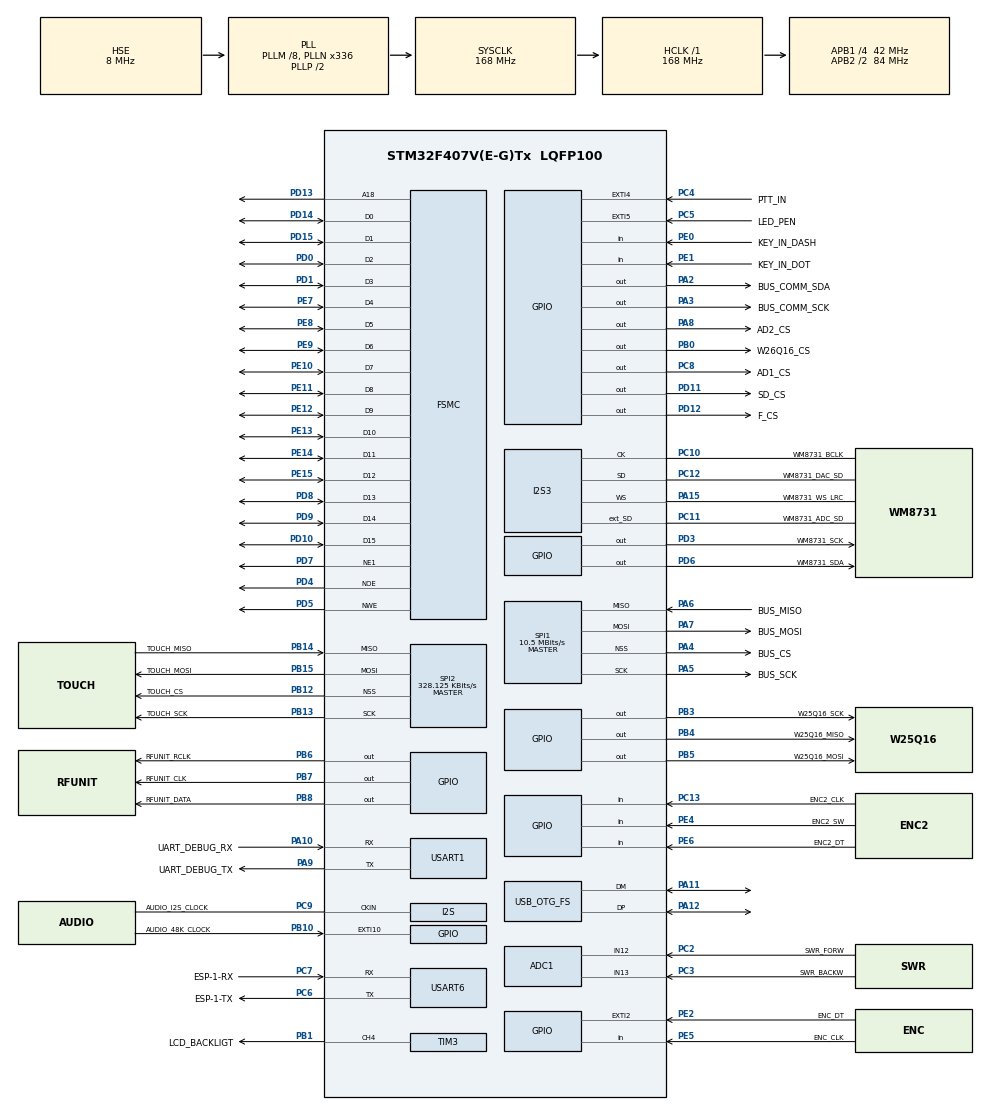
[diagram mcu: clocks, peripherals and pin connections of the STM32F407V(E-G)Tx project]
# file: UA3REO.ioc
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ADC1.Channel-0\#ChannelRegularConversion=ADC_CHANNEL_12
ADC1.NbrOfConversionFlag=1
ADC1.Rank-0\#ChannelRegularConversion=1
ADC1.SamplingTime-0\#ChannelRegularConversion=ADC_SAMPLETIME_3CYCLES
ADC1.master=1
Dma.I2S3_EXT_RX.0.Direction=DMA_PERIPH_TO_MEMORY
Dma.I2S3_EXT_RX.0.FIFOMode=DMA_FIFOMODE_ENABLE
Dma.I2S3_EXT_RX.0.FIFOThreshold=DMA_FIFO_THRESHOLD_FULL
Dma.I2S3_EXT_RX.0.Instance=DMA1_Stream0
Dma.I2S3_EXT_RX.0.MemBurst=DMA_MBURST_SINGLE
Dma.I2S3_EXT_RX.0.MemDataAlignment=DMA_MDATAALIGN_HALFWORD
Dma.I2S3_EXT_RX.0.MemInc=DMA_MINC_ENABLE
Dma.I2S3_EXT_RX.0.Mode=DMA_CIRCULAR
Dma.I2S3_EXT_RX.0.PeriphBurst=DMA_PBURST_SINGLE
Dma.I2S3_EXT_RX.0.PeriphDataAlignment=DMA_PDATAALIGN_HALFWORD
Dma.I2S3_EXT_RX.0.PeriphInc=DMA_PINC_DISABLE
Dma.I2S3_EXT_RX.0.Priority=DMA_PRIORITY_VERY_HIGH
Dma.MEMTOMEM.2.Direction=DMA_MEMORY_TO_MEMORY
Dma.MEMTOMEM.2.FIFOMode=DMA_FIFOMODE_ENABLE
Dma.MEMTOMEM.2.FIFOThreshold=DMA_FIFO_THRESHOLD_FULL
Dma.MEMTOMEM.2.Instance=DMA2_Stream0
Dma.MEMTOMEM.2.MemBurst=DMA_MBURST_INC4
Dma.MEMTOMEM.2.MemDataAlignment=DMA_MDATAALIGN_WORD
Dma.MEMTOMEM.2.MemInc=DMA_MINC_ENABLE
Dma.MEMTOMEM.2.Mode=DMA_NORMAL
Dma.MEMTOMEM.2.PeriphBurst=DMA_PBURST_INC4
Dma.MEMTOMEM.2.PeriphDataAlignment=DMA_PDATAALIGN_WORD
Dma.MEMTOMEM.2.PeriphInc=DMA_PINC_ENABLE
Dma.MEMTOMEM.2.Priority=DMA_PRIORITY_HIGH
Dma.MEMTOMEM.3.Direction=DMA_MEMORY_TO_MEMORY
Dma.MEMTOMEM.3.FIFOMode=DMA_FIFOMODE_ENABLE
Dma.MEMTOMEM.3.FIFOThreshold=DMA_FIFO_THRESHOLD_FULL
Dma.MEMTOMEM.3.Instance=DMA2_Stream1
Dma.MEMTOMEM.3.MemBurst=DMA_MBURST_INC4
Dma.MEMTOMEM.3.MemDataAlignment=DMA_MDATAALIGN_WORD
Dma.MEMTOMEM.3.MemInc=DMA_MINC_ENABLE
Dma.MEMTOMEM.3.Mode=DMA_NORMAL
Dma.MEMTOMEM.3.PeriphBurst=DMA_PBURST_INC4
Dma.MEMTOMEM.3.PeriphDataAlignment=DMA_PDATAALIGN_WORD
Dma.MEMTOMEM.3.PeriphInc=DMA_PINC_ENABLE
Dma.MEMTOMEM.3.Priority=DMA_PRIORITY_HIGH
Dma.MEMTOMEM.4.Direction=DMA_MEMORY_TO_MEMORY
Dma.MEMTOMEM.4.FIFOMode=DMA_FIFOMODE_ENABLE
Dma.MEMTOMEM.4.FIFOThreshold=DMA_FIFO_THRESHOLD_FULL
Dma.MEMTOMEM.4.Instance=DMA2_Stream7
Dma.MEMTOMEM.4.MemBurst=DMA_MBURST_INC4
Dma.MEMTOMEM.4.MemDataAlignment=DMA_MDATAALIGN_WORD
Dma.MEMTOMEM.4.MemInc=DMA_MINC_ENABLE
Dma.MEMTOMEM.4.Mode=DMA_NORMAL
Dma.MEMTOMEM.4.PeriphBurst=DMA_PBURST_INC4
Dma.MEMTOMEM.4.PeriphDataAlignment=DMA_PDATAALIGN_WORD
Dma.MEMTOMEM.4.PeriphInc=DMA_PINC_ENABLE
Dma.MEMTOMEM.4.Priority=DMA_PRIORITY_LOW
Dma.MEMTOMEM.5.Direction=DMA_MEMORY_TO_MEMORY
Dma.MEMTOMEM.5.FIFOMode=DMA_FIFOMODE_ENABLE
Dma.MEMTOMEM.5.FIFOThreshold=DMA_FIFO_THRESHOLD_FULL
Dma.MEMTOMEM.5.Instance=DMA2_Stream6
Dma.MEMTOMEM.5.MemBurst=DMA_MBURST_INC8
Dma.MEMTOMEM.5.MemDataAlignment=DMA_MDATAALIGN_HALFWORD
Dma.MEMTOMEM.5.MemInc=DMA_MINC_DISABLE
Dma.MEMTOMEM.5.Mode=DMA_NORMAL
Dma.MEMTOMEM.5.PeriphBurst=DMA_PBURST_INC8
Dma.MEMTOMEM.5.PeriphDataAlignment=DMA_PDATAALIGN_HALFWORD
Dma.MEMTOMEM.5.PeriphInc=DMA_PINC_ENABLE
Dma.MEMTOMEM.5.Priority=DMA_PRIORITY_LOW
Dma.MEMTOMEM.6.Direction=DMA_MEMORY_TO_MEMORY
Dma.MEMTOMEM.6.FIFOMode=DMA_FIFOMODE_ENABLE
Dma.MEMTOMEM.6.FIFOThreshold=DMA_FIFO_THRESHOLD_FULL
Dma.MEMTOMEM.6.Instance=DMA2_Stream5
Dma.MEMTOMEM.6.MemBurst=DMA_MBURST_INC8
Dma.MEMTOMEM.6.MemDataAlignment=DMA_MDATAALIGN_HALFWORD
Dma.MEMTOMEM.6.MemInc=DMA_MINC_DISABLE
Dma.MEMTOMEM.6.Mode=DMA_NORMAL
Dma.MEMTOMEM.6.PeriphBurst=DMA_PBURST_INC8
Dma.MEMTOMEM.6.PeriphDataAlignment=DMA_PDATAALIGN_HALFWORD
Dma.MEMTOMEM.6.PeriphInc=DMA_PINC_DISABLE
Dma.MEMTOMEM.6.Priority=DMA_PRIORITY_MEDIUM
Dma.MEMTOMEM.7.Direction=DMA_MEMORY_TO_MEMORY
Dma.MEMTOMEM.7.FIFOMode=DMA_FIFOMODE_ENABLE
Dma.MEMTOMEM.7.FIFOThreshold=DMA_FIFO_THRESHOLD_FULL
Dma.MEMTOMEM.7.Instance=DMA2_Stream3
Dma.MEMTOMEM.7.MemBurst=DMA_MBURST_INC4
Dma.MEMTOMEM.7.MemDataAlignment=DMA_MDATAALIGN_WORD
Dma.MEMTOMEM.7.MemInc=DMA_MINC_ENABLE
Dma.MEMTOMEM.7.Mode=DMA_NORMAL
Dma.MEMTOMEM.7.PeriphBurst=DMA_PBURST_INC4
Dma.MEMTOMEM.7.PeriphDataAlignment=DMA_PDATAALIGN_WORD
Dma.MEMTOMEM.7.PeriphInc=DMA_PINC_ENABLE
Dma.MEMTOMEM.7.Priority=DMA_PRIORITY_HIGH
Dma.Request0=I2S3_EXT_RX
Dma.Request1=SPI3_TX
Dma.Request2=MEMTOMEM
Dma.Request3=MEMTOMEM
Dma.Request4=MEMTOMEM
Dma.Request5=MEMTOMEM
Dma.Request6=MEMTOMEM
Dma.Request7=MEMTOMEM
Dma.Request8=USART6_RX
Dma.SPI3_TX.1.Direction=DMA_MEMORY_TO_PERIPH
Dma.SPI3_TX.1.FIFOMode=DMA_FIFOMODE_ENABLE
Dma.SPI3_TX.1.FIFOThreshold=DMA_FIFO_THRESHOLD_FULL
Dma.SPI3_TX.1.Instance=DMA1_Stream5
Dma.SPI3_TX.1.MemBurst=DMA_MBURST_SINGLE
Dma.SPI3_TX.1.MemDataAlignment=DMA_MDATAALIGN_HALFWORD
Dma.SPI3_TX.1.MemInc=DMA_MINC_ENABLE
Dma.SPI3_TX.1.Mode=DMA_CIRCULAR
Dma.SPI3_TX.1.PeriphBurst=DMA_PBURST_SINGLE
Dma.SPI3_TX.1.PeriphDataAlignment=DMA_PDATAALIGN_HALFWORD
Dma.SPI3_TX.1.PeriphInc=DMA_PINC_DISABLE
Dma.SPI3_TX.1.Priority=DMA_PRIORITY_VERY_HIGH
Dma.USART6_RX.8.Direction=DMA_PERIPH_TO_MEMORY
Dma.USART6_RX.8.FIFOMode=DMA_FIFOMODE_DISABLE
Dma.USART6_RX.8.Instance=DMA2_Stream2
Dma.USART6_RX.8.MemDataAlignment=DMA_MDATAALIGN_BYTE
Dma.USART6_RX.8.MemInc=DMA_MINC_ENABLE
Dma.USART6_RX.8.Mode=DMA_CIRCULAR
Dma.USART6_RX.8.PeriphDataAlignment=DMA_PDATAALIGN_BYTE
Dma.USART6_RX.8.PeriphInc=DMA_PINC_DISABLE
Dma.USART6_RX.8.Priority=DMA_PRIORITY_MEDIUM
FSMC.AddressSetupTime1=2
FSMC.BusTurnAroundDuration1=5
FSMC.DataSetupTime1=5
FSMC.ExtendedAddressSetupTime1=2
FSMC.ExtendedBusTurnAroundDuration1=3
FSMC.ExtendedDataSetupTime1=5
FSMC.ExtendedMode1=FSMC_EXTENDED_MODE_ENABLE
I2S3.AudioFreq=I2S_AUDIOFREQ_48K
I2S3.CPOL=I2S_CPOL_LOW
I2S3.ClockSource=I2S_CLOCK_EXTERNAL
I2S3.DataFormat=I2S_DATAFORMAT_32B
I2S3.ErrorAudioFreq=0.0 %
I2S3.FullDuplexMode=I2S_FULLDUPLEXMODE_ENABLE
I2S3.Instance=SPI$Index
I2S3.Mode=I2S_MODE_MASTER_TX
I2S3.RealAudioFreq=48.0 KHz
I2S3.Standard=I2S_STANDARD_PHILIPS
I2S3.VirtualMode=I2S_MODE_MASTER
IWDG.Prescaler=IWDG_PRESCALER_32
Mcu.Family=STM32F4
Mcu.Name=STM32F407V(E-G)Tx
Mcu.Package=LQFP100
NVIC.DMA1_Stream0_IRQn=true\:0\:0\:false\:false\:true\:false\:true
NVIC.DMA1_Stream5_IRQn=true\:0\:0\:false\:false\:true\:false\:true
NVIC.DMA2_Stream0_IRQn=true\:4\:0\:true\:false\:true\:true\:true
NVIC.DMA2_Stream1_IRQn=true\:4\:0\:true\:false\:true\:true\:true
NVIC.DMA2_Stream2_IRQn=true\:0\:0\:false\:false\:true\:false\:true
NVIC.DMA2_Stream3_IRQn=true\:0\:0\:false\:false\:true\:true\:true
NVIC.DMA2_Stream6_IRQn=true\:5\:0\:true\:false\:true\:true\:true
NVIC.EXTI15_10_IRQn=true\:2\:0\:true\:false\:true\:true\:true
NVIC.EXTI2_IRQn=true\:3\:0\:true\:false\:true\:true\:true
NVIC.EXTI4_IRQn=true\:6\:0\:true\:false\:true\:true\:true
NVIC.EXTI9_5_IRQn=true\:5\:0\:true\:false\:true\:true\:true
NVIC.OTG_FS_IRQn=true\:1\:0\:true\:false\:true\:true\:true
NVIC.PriorityGroup=NVIC_PRIORITYGROUP_4
NVIC.SPI1_IRQn=true\:0\:0\:true\:false\:true\:true\:true
NVIC.TIM4_IRQn=true\:8\:0\:true\:false\:true\:true\:true
NVIC.TIM5_IRQn=true\:4\:0\:true\:false\:true\:true\:true
NVIC.TIM6_DAC_IRQn=true\:7\:0\:true\:false\:true\:true\:true
NVIC.TIM7_IRQn=true\:9\:0\:true\:false\:true\:true\:true
NVIC.USART6_IRQn=true\:0\:0\:false\:false\:true\:true\:true
PA10.GPIO_Label=UART_DEBUG_RX
PA10.GPIO_Speed=GPIO_SPEED_FREQ_MEDIUM
PA10.Mode=Asynchronous
PA10.Signal=USART1_RX
PA11.Mode=Device_Only
PA11.Signal=USB_OTG_FS_DM
PA12.Mode=Device_Only
PA12.Signal=USB_OTG_FS_DP
PA13.Mode=Serial_Wire
PA13.Signal=SYS_JTMS-SWDIO
PA14.Mode=Serial_Wire
PA14.Signal=SYS_JTCK-SWCLK
PA15.GPIO_Label=WM8731_WS_LRC
PA15.GPIO_PuPd=GPIO_PULLUP
PA15.GPIO_Speed=GPIO_SPEED_FREQ_VERY_HIGH
PA15.Mode=Full_Duplex_Master
PA15.Signal=I2S3_WS
PA2.GPIO_Label=BUS_COMM_SDA
PA2.GPIO_PuPd=GPIO_PULLUP
PA2.Signal=GPIO_Output
PA3.GPIO_Label=BUS_COMM_SCK
PA3.GPIO_PuPd=GPIO_PULLUP
PA3.Signal=GPIO_Output
PA4.GPIO_Label=BUS_CS
PA4.GPIO_PuPd=GPIO_PULLUP
PA4.Mode=NSS_Signal_Hard_Output
PA4.Signal=SPI1_NSS
PA5.GPIO_Label=BUS_SCK
PA5.GPIO_PuPd=GPIO_PULLUP
PA5.GPIO_Speed=GPIO_SPEED_FREQ_VERY_HIGH
PA5.Mode=Full_Duplex_Master
PA5.Signal=SPI1_SCK
PA6.GPIO_Label=BUS_MISO
PA6.GPIO_PuPd=GPIO_PULLUP
PA6.GPIO_Speed=GPIO_SPEED_FREQ_VERY_HIGH
PA6.Mode=Full_Duplex_Master
PA6.Signal=SPI1_MISO
PA7.GPIO_Label=BUS_MOSI
PA7.GPIO_PuPd=GPIO_PULLUP
PA7.GPIO_Speed=GPIO_SPEED_FREQ_VERY_HIGH
PA7.Mode=Full_Duplex_Master
PA7.Signal=SPI1_MOSI
PA8.GPIO_Label=AD2_CS
PA8.Signal=GPIO_Output
PA9.GPIO_Label=UART_DEBUG_TX
PA9.GPIO_Speed=GPIO_SPEED_FREQ_MEDIUM
PA9.Mode=Asynchronous
PA9.Signal=USART1_TX
PB0.GPIO_Label=W26Q16_CS
PB0.GPIO_PuPd=GPIO_PULLUP
PB0.GPIO_Speed=GPIO_SPEED_FREQ_VERY_HIGH
PB0.Signal=GPIO_Output
PB1.GPIO_Label=LCD_BACKLIGT
PB1.GPIO_Speed=GPIO_SPEED_FREQ_LOW
PB1.Signal=S_TIM3_CH4
PB10.GPIO_Label=AUDIO_48K_CLOCK
PB10.GPIO_PuPd=GPIO_PULLUP
PB10.Signal=GPXTI10
PB12.GPIO_Label=TOUCH_CS
PB12.GPIO_PuPd=GPIO_PULLUP
PB12.GPIO_Speed=GPIO_SPEED_FREQ_HIGH
PB12.Mode=NSS_Signal_Hard_Output
PB12.Signal=SPI2_NSS
PB13.GPIO_Label=TOUCH_SCK
PB13.GPIO_PuPd=GPIO_PULLUP
PB13.GPIO_Speed=GPIO_SPEED_FREQ_HIGH
PB13.Mode=Full_Duplex_Master
PB13.Signal=SPI2_SCK
PB14.GPIO_Label=TOUCH_MISO
PB14.GPIO_PuPd=GPIO_PULLUP
PB14.GPIO_Speed=GPIO_SPEED_FREQ_HIGH
PB14.Mode=Full_Duplex_Master
PB14.Signal=SPI2_MISO
PB15.GPIO_Label=TOUCH_MOSI
PB15.GPIO_PuPd=GPIO_PULLUP
PB15.GPIO_Speed=GPIO_SPEED_FREQ_HIGH
PB15.Mode=Full_Duplex_Master
PB15.Signal=SPI2_MOSI
PB3.GPIO_Label=W25Q16_SCK
PB3.Signal=GPIO_Output
PB4.GPIO_Label=W25Q16_MISO
PB4.Signal=GPIO_Output
PB5.GPIO_Label=W25Q16_MOSI
PB5.Signal=GPIO_Output
PB6.GPIO_Label=RFUNIT_RCLK
PB6.GPIO_PuPd=GPIO_PULLUP
PB6.Signal=GPIO_Output
PB7.GPIO_Label=RFUNIT_CLK
PB7.GPIO_PuPd=GPIO_PULLUP
PB7.Signal=GPIO_Output
PB8.GPIO_Label=RFUNIT_DATA
PB8.GPIO_PuPd=GPIO_PULLUP
PB8.Signal=GPIO_Output
PC10.GPIO_Label=WM8731_BCLK
PC10.GPIO_PuPd=GPIO_PULLUP
PC10.GPIO_Speed=GPIO_SPEED_FREQ_VERY_HIGH
PC10.Mode=Full_Duplex_Master
PC10.Signal=I2S3_CK
PC11.GPIO_Label=WM8731_ADC_SD
PC11.GPIO_PuPd=GPIO_PULLUP
PC11.GPIO_Speed=GPIO_SPEED_FREQ_VERY_HIGH
PC11.Mode=Full_Duplex_Master
PC11.Signal=I2S3_ext_SD
PC12.GPIO_Label=WM8731_DAC_SD
PC12.GPIO_PuPd=GPIO_PULLUP
PC12.GPIO_Speed=GPIO_SPEED_FREQ_VERY_HIGH
PC12.Mode=Full_Duplex_Master
PC12.Signal=I2S3_SD
PC13-ANTI_TAMP.GPIO_Label=ENC2_CLK
PC13-ANTI_TAMP.Signal=GPIO_Input
PC14-OSC32_IN.Mode=LSE-External-Oscillator
PC14-OSC32_IN.Signal=RCC_OSC32_IN
PC15-OSC32_OUT.Mode=LSE-External-Oscillator
PC15-OSC32_OUT.Signal=RCC_OSC32_OUT
PC2.GPIO_Label=SWR_FORW
PC2.Signal=ADCx_IN12
PC3.GPIO_Label=SWR_BACKW
PC3.Signal=ADCx_IN13
PC4.GPIO_Label=PTT_IN
PC4.GPIO_PuPd=GPIO_PULLUP
PC4.Signal=GPXTI4
PC5.GPIO_Label=LED_PEN
PC5.GPIO_ModeDefaultEXTI=GPIO_MODE_IT_RISING_FALLING
PC5.GPIO_PuPd=GPIO_PULLUP
PC5.Signal=GPXTI5
PC6.GPIO_Label=ESP-1-TX
PC6.Mode=Asynchronous
PC6.Signal=USART6_TX
PC7.GPIO_Label=ESP-1-RX
PC7.Mode=Asynchronous
PC7.Signal=USART6_RX
PC8.GPIO_Label=AD1_CS
PC8.Signal=GPIO_Output
PC9.GPIO_Label=AUDIO_I2S_CLOCK
PC9.GPIO_PuPd=GPIO_PULLUP
PC9.GPIO_Speed=GPIO_SPEED_FREQ_VERY_HIGH
PC9.Mode=Audio_ClockIn
PC9.Signal=I2S_CKIN
PD0.GPIO_PuPd=GPIO_PULLUP
PD0.GPIO_Speed_High_Default=GPIO_SPEED_FREQ_LOW
PD0.Mode=16b-d1
PD0.Signal=FSMC_D2
PD1.GPIO_PuPd=GPIO_PULLUP
PD1.GPIO_Speed_High_Default=GPIO_SPEED_FREQ_LOW
PD1.Mode=16b-d1
PD1.Signal=FSMC_D3
PD10.GPIO_PuPd=GPIO_PULLUP
PD10.GPIO_Speed_High_Default=GPIO_SPEED_FREQ_LOW
PD10.Mode=16b-d1
PD10.Signal=FSMC_D15
PD11.GPIO_Label=SD_CS
PD11.Signal=GPIO_Output
PD12.GPIO_Label=F_CS
PD12.Signal=GPIO_Output
PD13.GPIO_PuPd=GPIO_PULLUP
PD13.GPIO_Speed_High_Default=GPIO_SPEED_FREQ_LOW
PD13.Mode=A18_1
PD13.Signal=FSMC_A18
PD14.GPIO_PuPd=GPIO_PULLUP
PD14.GPIO_Speed_High_Default=GPIO_SPEED_FREQ_LOW
PD14.Mode=16b-d1
PD14.Signal=FSMC_D0
PD15.GPIO_PuPd=GPIO_PULLUP
PD15.GPIO_Speed_High_Default=GPIO_SPEED_FREQ_LOW
PD15.Mode=16b-d1
PD15.Signal=FSMC_D1
PD3.GPIO_Label=WM8731_SCK
PD3.GPIO_PuPd=GPIO_PULLUP
PD3.GPIO_Speed=GPIO_SPEED_FREQ_LOW
PD3.Signal=GPIO_Output
PD4.GPIO_PuPd=GPIO_PULLUP
PD4.GPIO_Speed_High_Default=GPIO_SPEED_FREQ_LOW
PD4.Mode=Lcd1
PD4.Signal=FSMC_NOE
PD5.GPIO_PuPd=GPIO_PULLUP
PD5.GPIO_Speed_High_Default=GPIO_SPEED_FREQ_LOW
PD5.Mode=Lcd1
PD5.Signal=FSMC_NWE
PD6.GPIO_Label=WM8731_SDA
PD6.GPIO_PuPd=GPIO_PULLUP
PD6.GPIO_Speed=GPIO_SPEED_FREQ_LOW
PD6.Signal=GPIO_Output
PD7.GPIO_PuPd=GPIO_PULLUP
PD7.GPIO_Speed_High_Default=GPIO_SPEED_FREQ_LOW
PD7.Mode=NorPsramChipSelect1_1
PD7.Signal=FSMC_NE1
PD8.GPIO_PuPd=GPIO_PULLUP
PD8.GPIO_Speed_High_Default=GPIO_SPEED_FREQ_LOW
PD8.Mode=16b-d1
PD8.Signal=FSMC_D13
PD9.GPIO_PuPd=GPIO_PULLUP
PD9.GPIO_Speed_High_Default=GPIO_SPEED_FREQ_LOW
PD9.Mode=16b-d1
PD9.Signal=FSMC_D14
PE0.GPIO_Label=KEY_IN_DASH
PE0.GPIO_PuPd=GPIO_PULLUP
PE0.Signal=GPIO_Input
PE1.GPIO_Label=KEY_IN_DOT
PE1.GPIO_PuPd=GPIO_PULLUP
PE1.Signal=GPIO_Input
PE10.GPIO_PuPd=GPIO_PULLUP
PE10.GPIO_Speed_High_Default=GPIO_SPEED_FREQ_LOW
PE10.Mode=16b-d1
PE10.Signal=FSMC_D7
PE11.GPIO_PuPd=GPIO_PULLUP
PE11.GPIO_Speed_High_Default=GPIO_SPEED_FREQ_LOW
PE11.Mode=16b-d1
PE11.Signal=FSMC_D8
PE12.GPIO_PuPd=GPIO_PULLUP
PE12.GPIO_Speed_High_Default=GPIO_SPEED_FREQ_LOW
PE12.Mode=16b-d1
PE12.Signal=FSMC_D9
PE13.GPIO_PuPd=GPIO_PULLUP
PE13.GPIO_Speed_High_Default=GPIO_SPEED_FREQ_LOW
PE13.Mode=16b-d1
PE13.Signal=FSMC_D10
PE14.GPIO_PuPd=GPIO_PULLUP
PE14.GPIO_Speed_High_Default=GPIO_SPEED_FREQ_LOW
PE14.Mode=16b-d1
PE14.Signal=FSMC_D11
PE15.GPIO_PuPd=GPIO_PULLUP
PE15.GPIO_Speed_High_Default=GPIO_SPEED_FREQ_LOW
PE15.Mode=16b-d1
PE15.Signal=FSMC_D12
PE2.GPIO_Label=ENC_DT
PE2.GPIO_ModeDefaultEXTI=GPIO_MODE_IT_RISING_FALLING
PE2.GPIO_PuPd=GPIO_PULLUP
PE2.Signal=GPXTI2
PE4.GPIO_Label=ENC2_SW
PE4.Signal=GPIO_Input
PE5.GPIO_Label=ENC_CLK
PE5.GPIO_PuPd=GPIO_PULLUP
PE5.Signal=GPIO_Input
PE6.GPIO_Label=ENC2_DT
PE6.Signal=GPIO_Input
PE7.GPIO_PuPd=GPIO_PULLUP
PE7.GPIO_Speed_High_Default=GPIO_SPEED_FREQ_LOW
PE7.Mode=16b-d1
PE7.Signal=FSMC_D4
PE8.GPIO_PuPd=GPIO_PULLUP
PE8.GPIO_Speed_High_Default=GPIO_SPEED_FREQ_LOW
PE8.Mode=16b-d1
PE8.Signal=FSMC_D5
PE9.GPIO_PuPd=GPIO_PULLUP
PE9.GPIO_Speed_High_Default=GPIO_SPEED_FREQ_LOW
PE9.Mode=16b-d1
PE9.Signal=FSMC_D6
PH0-OSC_IN.Mode=HSE-External-Oscillator
PH0-OSC_IN.Signal=RCC_OSC_IN
PH1-OSC_OUT.Mode=HSE-External-Oscillator
PH1-OSC_OUT.Signal=RCC_OSC_OUT
ProjectManager.HeapSize=0x600
ProjectManager.StackSize=0xA00
ProjectManager.TargetToolchain=MDK-ARM V5
RCC.48MHZClocksFreq_Value=48000000
RCC.AHBFreq_Value=168000000
RCC.APB1CLKDivider=RCC_HCLK_DIV4
RCC.APB1Freq_Value=42000000
RCC.APB1TimFreq_Value=84000000
RCC.APB2CLKDivider=RCC_HCLK_DIV2
RCC.APB2Freq_Value=84000000
RCC.APB2TimFreq_Value=168000000
RCC.CortexFreq_Value=168000000
RCC.EXTERNAL_CLOCK_VALUE=12288000
RCC.EnbaleCSS=true
RCC.HCLKFreq_Value=168000000
RCC.HSE_VALUE=8000000
RCC.HSI_VALUE=16000000
RCC.I2SClockSource=I2S_CLOCK_EXTERNAL
RCC.PLLI2SN=384
RCC.PLLM=8
RCC.PLLN=336
RCC.PLLQ=7
RCC.RCC_RTC_Clock_Source=RCC_RTCCLKSOURCE_LSE
RCC.RCC_RTC_Clock_SourceVirtual=RCC_RTCCLKSOURCE_HSE_DIV8
RCC.RCC_RTC_Clock_Source_FROM_HSE=RCC_RTCCLKSOURCE_HSE_DIV8
RCC.SYSCLKFreq_VALUE=168000000
RCC.SYSCLKSource=RCC_SYSCLKSOURCE_PLLCLK
RCC.VCOOutputFreq_Value=336000000
RTC.SynchPrediv=255
SH.ADCx_IN12.0=ADC1_IN12,IN12
SH.ADCx_IN13.0=ADC1_IN13,IN13
SH.S_TIM3_CH4.0=TIM3_CH4,PWM Generation4 CH4
SPI1.BaudRatePrescaler=SPI_BAUDRATEPRESCALER_8
SPI1.CLKPhase=SPI_PHASE_1EDGE
SPI1.CLKPolarity=SPI_POLARITY_LOW
SPI1.CalculateBaudRate=10.5 MBits/s
SPI1.Direction=SPI_DIRECTION_2LINES
SPI1.Mode=SPI_MODE_MASTER
SPI1.VirtualNSS=VM_NSSHARD
SPI1.VirtualType=VM_MASTER
SPI2.BaudRatePrescaler=SPI_BAUDRATEPRESCALER_128
SPI2.CalculateBaudRate=328.125 KBits/s
SPI2.Direction=SPI_DIRECTION_2LINES
SPI2.Mode=SPI_MODE_MASTER
SPI2.VirtualNSS=VM_NSSHARD
SPI2.VirtualType=VM_MASTER
TIM3.Channel-PWM\ Generation4\ CH4=TIM_CHANNEL_4
TIM3.Period=65535
TIM3.Prescaler=0
TIM4.Period=1
TIM4.Prescaler=800
TIM4.TIM_MasterOutputTrigger=TIM_TRGO_UPDATE
TIM5.Period=1
TIM5.Prescaler=873
TIM5.TIM_MasterOutputTrigger=TIM_TRGO_UPDATE
TIM6.Period=99
TIM6.Prescaler=41999
TIM6.TIM_MasterOutputTrigger=TIM_TRGO_UPDATE
TIM7.Period=1
TIM7.Prescaler=800
TIM7.TIM_MasterOutputTrigger=TIM_TRGO_UPDATE
USART1.VirtualMode=VM_ASYNC
USART6.VirtualMode=VM_ASYNC
USB_OTG_FS.Sof_enable=ENABLE
USB_OTG_FS.VirtualMode=Device_Only
VP_IWDG_VS_IWDG.Mode=IWDG_Activate
VP_RTC_VS_RTC_Activate.Mode=RTC_Enabled
VP_TIM3_VS_ClockSourceINT.Mode=Internal
VP_TIM4_VS_ClockSourceINT.Mode=Internal
VP_TIM5_VS_ClockSourceINT.Mode=Internal
VP_TIM6_VS_ClockSourceINT.Mode=Enable_Timer
VP_TIM7_VS_ClockSourceINT.Mode=Enable_Timer
board=custom

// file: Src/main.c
/* USER CODE BEGIN Header */
/**
  ******************************************************************************
  * @file           : main.c
  * @brief          : Main program body
  ******************************************************************************
  * @attention
  *
  * <h2><center>&copy; Copyright (c) 2019 STMicroelectronics.
  * All rights reserved.</center></h2>
  *
  * This software component is licensed by ST under Ultimate Liberty license
  * SLA0044, the "License"; You may not use this file except in compliance with
  * the License. You may obtain a copy of the License at:
  *                             www.st.com/SLA0044
  *
  ******************************************************************************
  */
/* USER CODE END Header */

#include "main.h"

/* USER CODE BEGIN Includes */
#include "LCD/lcd_driver.h"
#include "LCD/xpt2046_spi.h"
#include "functions.h"
#include "bootloader.h"
#include "trx_manager.h"
#include "lcd.h"
#include "encoder.h"
#include "fpga.h"
#include "fft.h"
#include "wm8731.h"
#include "audio_processor.h"
#include "settings.h"
#include "profiler.h"
#include "usb_device.h"
#include "usbd_cat_if.h"
#include "wifi.h"
/* USER CODE END Includes */

ADC_HandleTypeDef hadc1;

I2S_HandleTypeDef hi2s3;
DMA_HandleTypeDef hdma_i2s3_ext_rx;
DMA_HandleTypeDef hdma_spi3_tx;

IWDG_HandleTypeDef hiwdg;

RTC_HandleTypeDef hrtc;

SPI_HandleTypeDef hspi1;
SPI_HandleTypeDef hspi2;

TIM_HandleTypeDef htim3;
TIM_HandleTypeDef htim4;
TIM_HandleTypeDef htim5;
TIM_HandleTypeDef htim6;
TIM_HandleTypeDef htim7;

UART_HandleTypeDef huart1;
UART_HandleTypeDef huart6;
DMA_HandleTypeDef hdma_usart6_rx;

PCD_HandleTypeDef hpcd_USB_OTG_FS;

DMA_HandleTypeDef hdma_memtomem_dma2_stream0;
DMA_HandleTypeDef hdma_memtomem_dma2_stream1;
DMA_HandleTypeDef hdma_memtomem_dma2_stream7;
DMA_HandleTypeDef hdma_memtomem_dma2_stream6;
DMA_HandleTypeDef hdma_memtomem_dma2_stream5;
DMA_HandleTypeDef hdma_memtomem_dma2_stream3;
SRAM_HandleTypeDef hsram1;

/* USER CODE BEGIN PV */
/* Private variables ---------------------------------------------------------*/
volatile uint32_t cpu_sleep_counter=0;
/* USER CODE END PV */

void SystemClock_Config(void);
static void MX_GPIO_Init(void);
static void MX_DMA_Init(void);
static void MX_FSMC_Init(void);
static void MX_TIM6_Init(void);
static void MX_I2S3_Init(void);
static void MX_TIM5_Init(void);
static void MX_SPI2_Init(void);
static void MX_SPI1_Init(void);
static void MX_TIM4_Init(void);
static void MX_RTC_Init(void);
static void MX_USART1_UART_Init(void);
static void MX_TIM3_Init(void);
static void MX_IWDG_Init(void);
static void MX_USB_OTG_FS_PCD_Init(void);
static void MX_ADC1_Init(void);
static void MX_TIM7_Init(void);
static void MX_USART6_UART_Init(void);
/* USER CODE BEGIN PFP */
/* Private function prototypes -----------------------------------------------*/

/* USER CODE END PFP */

int main(void)
{

  /* MCU Configuration--------------------------------------------------------*/

  /* Reset of all peripherals, Initializes the Flash interface and the Systick. */
  HAL_Init();

  /* USER CODE BEGIN Init */
	//checkBootloaderButton(); //Go to bootloader if (K0 PE4) pressed
  /* USER CODE END Init */

  /* Configure the system clock */
  SystemClock_Config();

  /* USER CODE BEGIN SysInit */
	MX_GPIO_Init();
	TRX_RF_UNIT_UpdateState(true);
  /* USER CODE END SysInit */

  /* Initialize all configured peripherals */
  MX_GPIO_Init();
  MX_DMA_Init();
  MX_FSMC_Init();
  MX_TIM6_Init();
  MX_I2S3_Init();
  MX_TIM5_Init();
  MX_SPI2_Init();
  MX_SPI1_Init();
  MX_TIM4_Init();
  MX_RTC_Init();
  MX_USART1_UART_Init();
  MX_TIM3_Init();
  MX_IWDG_Init();
  MX_ADC1_Init();
  MX_TIM7_Init();
  MX_USART6_UART_Init();
  /* USER CODE BEGIN 2 */
	MX_USB_DEVICE_Init();
	/* BUG FIX: Enabling Audio Clock Input in CubeMX does not set I2SSRC bit in RCC_CFGR register! Hence we need to set it manually here!
	  WARNING: A bug fix is also needed in __HAL_RCC_GET_I2S_SOURCE()
		Line 6131 stm32f4xx_hal_rcc_ex.h -> #define __HAL_RCC_GET_I2S_SOURCE() ((uint32_t)(READ_BIT(RCC->CFGR, RCC_CFGR_I2SSRC)) >> RCC_CFGR_I2SSRC_Pos)
	*/

	/*
	while(true)
	{
		i2c_begin(I2C_FPGA);
		i2c_beginTransmission_u8(I2C_FPGA, B8(1110010)); //I2C_ADDRESS
		i2c_write_u8(I2C_FPGA, 100);
		uint8_t st = i2c_endTransmission(I2C_FPGA);
		//sendToDebug_uint8(st,false);
		//sendToDebug_flush();

		i2c_begin(I2C_FPGA);
		i2c_requestFrom_ii(I2C_FPGA, B8(1110010), 3);
		sendToDebug_uint8(i2c_read(I2C_FPGA),false);
		sendToDebug_uint8(i2c_read(I2C_FPGA),false);
		sendToDebug_uint8(i2c_read(I2C_FPGA),false);
		sendToDebug_flush();

		sendToDebug_newline();

		HAL_IWDG_Refresh(&hiwdg);

		HAL_Delay(1000);
	}
	*/

	SPI_Bus_Buffer_TX[0]=1; //Q-M
	SPI_Bus_Buffer_TX[1]=2; //Q-L
	SPI_Bus_Buffer_TX[2]=4; //I-M
	SPI_Bus_Buffer_TX[3]=8; //I-L
	HAL_RTC_Init(&hrtc);
	InitProfiler();
	sendToDebug_str("\r\n");
	HAL_TIM_PWM_Start(&htim3, TIM_CHANNEL_4); //LCD backlight
	LoadSettings();
	LCD_Init();
	if(!TRX.Calibrated)
	{
		//Touch_Calibrate();
		LCD_Init();
		SaveSettings();
	}
	FFT_Init();
	WM8731_Init();
	TRX_Init();
	ENCODER_Init();
	FPGA_Init();
	initAudioProcessor();
	HAL_TIM_Base_Start(&htim5);
	HAL_TIM_Base_Start_IT(&htim5);
	HAL_TIM_Base_Start(&htim6);
	HAL_TIM_Base_Start_IT(&htim6);
	HAL_TIM_Base_Start(&htim4);
	HAL_TIM_Base_Start_IT(&htim4);
	HAL_TIM_Base_Start(&htim7);
	HAL_TIM_Base_Start_IT(&htim7);
	TRX_RF_UNIT_UpdateState(false);

	sendToDebug_str("UA3REO Started\r\n\r\n");
	TRX_inited = true;
  /* USER CODE END 2 */

  /* Infinite loop */
	while (1)
	{

    /* USER CODE BEGIN 3 */
		HAL_IWDG_Refresh(&hiwdg);
		cpu_sleep_counter++;
		__WFI();
	}
  /* USER CODE END 3 */
}

void SystemClock_Config(void)
{
  RCC_OscInitTypeDef RCC_OscInitStruct = {0};
  RCC_ClkInitTypeDef RCC_ClkInitStruct = {0};
  RCC_PeriphCLKInitTypeDef PeriphClkInitStruct = {0};

  /** Configure the main internal regulator output voltage
  */
  __HAL_RCC_PWR_CLK_ENABLE();
  __HAL_PWR_VOLTAGESCALING_CONFIG(PWR_REGULATOR_VOLTAGE_SCALE1);
  /** Initializes the CPU, AHB and APB busses clocks
  */
  RCC_OscInitStruct.OscillatorType = RCC_OSCILLATORTYPE_LSI|RCC_OSCILLATORTYPE_HSE
                              |RCC_OSCILLATORTYPE_LSE;
  RCC_OscInitStruct.HSEState = RCC_HSE_ON;
  RCC_OscInitStruct.LSEState = RCC_LSE_ON;
  RCC_OscInitStruct.LSIState = RCC_LSI_ON;
  RCC_OscInitStruct.PLL.PLLState = RCC_PLL_ON;
  RCC_OscInitStruct.PLL.PLLSource = RCC_PLLSOURCE_HSE;
  RCC_OscInitStruct.PLL.PLLM = 8;
  RCC_OscInitStruct.PLL.PLLN = 336;
  RCC_OscInitStruct.PLL.PLLP = RCC_PLLP_DIV2;
  RCC_OscInitStruct.PLL.PLLQ = 7;
  if (HAL_RCC_OscConfig(&RCC_OscInitStruct) != HAL_OK)
  {
    Error_Handler();
  }
  /** Initializes the CPU, AHB and APB busses clocks
  */
  RCC_ClkInitStruct.ClockType = RCC_CLOCKTYPE_HCLK|RCC_CLOCKTYPE_SYSCLK
                              |RCC_CLOCKTYPE_PCLK1|RCC_CLOCKTYPE_PCLK2;
  RCC_ClkInitStruct.SYSCLKSource = RCC_SYSCLKSOURCE_PLLCLK;
  RCC_ClkInitStruct.AHBCLKDivider = RCC_SYSCLK_DIV1;
  RCC_ClkInitStruct.APB1CLKDivider = RCC_HCLK_DIV4;
  RCC_ClkInitStruct.APB2CLKDivider = RCC_HCLK_DIV2;

  if (HAL_RCC_ClockConfig(&RCC_ClkInitStruct, FLASH_LATENCY_5) != HAL_OK)
  {
    Error_Handler();
  }
  PeriphClkInitStruct.PeriphClockSelection = RCC_PERIPHCLK_RTC;
  PeriphClkInitStruct.RTCClockSelection = RCC_RTCCLKSOURCE_LSE;
  if (HAL_RCCEx_PeriphCLKConfig(&PeriphClkInitStruct) != HAL_OK)
  {
    Error_Handler();
  }
  /** Enables the Clock Security System
  */
  HAL_RCC_EnableCSS();
}

static void MX_ADC1_Init(void)
{

  ADC_ChannelConfTypeDef sConfig = {0};

  /** Configure the global features of the ADC (Clock, Resolution, Data Alignment and number of conversion)
  */
  hadc1.Instance = ADC1;
  hadc1.Init.ClockPrescaler = ADC_CLOCK_SYNC_PCLK_DIV4;
  hadc1.Init.Resolution = ADC_RESOLUTION_12B;
  hadc1.Init.ScanConvMode = DISABLE;
  hadc1.Init.ContinuousConvMode = DISABLE;
  hadc1.Init.DiscontinuousConvMode = DISABLE;
  hadc1.Init.ExternalTrigConvEdge = ADC_EXTERNALTRIGCONVEDGE_NONE;
  hadc1.Init.ExternalTrigConv = ADC_SOFTWARE_START;
  hadc1.Init.DataAlign = ADC_DATAALIGN_RIGHT;
  hadc1.Init.NbrOfConversion = 1;
  hadc1.Init.DMAContinuousRequests = DISABLE;
  hadc1.Init.EOCSelection = ADC_EOC_SINGLE_CONV;
  if (HAL_ADC_Init(&hadc1) != HAL_OK)
  {
    Error_Handler();
  }
  /** Configure for the selected ADC regular channel its corresponding rank in the sequencer and its sample time.
  */
  sConfig.Channel = ADC_CHANNEL_12;
  sConfig.Rank = 1;
  sConfig.SamplingTime = ADC_SAMPLETIME_3CYCLES;
  if (HAL_ADC_ConfigChannel(&hadc1, &sConfig) != HAL_OK)
  {
    Error_Handler();
  }

}

static void MX_I2S3_Init(void)
{

  hi2s3.Instance = SPI3;
  hi2s3.Init.Mode = I2S_MODE_MASTER_TX;
  hi2s3.Init.Standard = I2S_STANDARD_PHILIPS;
  hi2s3.Init.DataFormat = I2S_DATAFORMAT_32B;
  hi2s3.Init.MCLKOutput = I2S_MCLKOUTPUT_DISABLE;
  hi2s3.Init.AudioFreq = I2S_AUDIOFREQ_48K;
  hi2s3.Init.CPOL = I2S_CPOL_LOW;
  hi2s3.Init.ClockSource = I2S_CLOCK_EXTERNAL;
  hi2s3.Init.FullDuplexMode = I2S_FULLDUPLEXMODE_ENABLE;
  if (HAL_I2S_Init(&hi2s3) != HAL_OK)
  {
    Error_Handler();
  }

}

static void MX_IWDG_Init(void)
{

  hiwdg.Instance = IWDG;
  hiwdg.Init.Prescaler = IWDG_PRESCALER_32;
  hiwdg.Init.Reload = 4095;
  if (HAL_IWDG_Init(&hiwdg) != HAL_OK)
  {
    Error_Handler();
  }

}

static void MX_RTC_Init(void)
{

  /** Initialize RTC Only
  */
  hrtc.Instance = RTC;
  hrtc.Init.HourFormat = RTC_HOURFORMAT_24;
  hrtc.Init.AsynchPrediv = 127;
  hrtc.Init.SynchPrediv = 255;
  hrtc.Init.OutPut = RTC_OUTPUT_DISABLE;
  hrtc.Init.OutPutPolarity = RTC_OUTPUT_POLARITY_HIGH;
  hrtc.Init.OutPutType = RTC_OUTPUT_TYPE_OPENDRAIN;
  if (HAL_RTC_Init(&hrtc) != HAL_OK)
  {
    Error_Handler();
  }

}

static void MX_SPI1_Init(void)
{

  /* SPI1 parameter configuration*/
  hspi1.Instance = SPI1;
  hspi1.Init.Mode = SPI_MODE_MASTER;
  hspi1.Init.Direction = SPI_DIRECTION_2LINES;
  hspi1.Init.DataSize = SPI_DATASIZE_8BIT;
  hspi1.Init.CLKPolarity = SPI_POLARITY_LOW;
  hspi1.Init.CLKPhase = SPI_PHASE_1EDGE;
  hspi1.Init.NSS = SPI_NSS_HARD_OUTPUT;
  hspi1.Init.BaudRatePrescaler = SPI_BAUDRATEPRESCALER_8;
  hspi1.Init.FirstBit = SPI_FIRSTBIT_MSB;
  hspi1.Init.TIMode = SPI_TIMODE_DISABLE;
  hspi1.Init.CRCCalculation = SPI_CRCCALCULATION_DISABLE;
  hspi1.Init.CRCPolynomial = 10;
  if (HAL_SPI_Init(&hspi1) != HAL_OK)
  {
    Error_Handler();
  }

}

static void MX_SPI2_Init(void)
{

  /* SPI2 parameter configuration*/
  hspi2.Instance = SPI2;
  hspi2.Init.Mode = SPI_MODE_MASTER;
  hspi2.Init.Direction = SPI_DIRECTION_2LINES;
  hspi2.Init.DataSize = SPI_DATASIZE_8BIT;
  hspi2.Init.CLKPolarity = SPI_POLARITY_LOW;
  hspi2.Init.CLKPhase = SPI_PHASE_1EDGE;
  hspi2.Init.NSS = SPI_NSS_HARD_OUTPUT;
  hspi2.Init.BaudRatePrescaler = SPI_BAUDRATEPRESCALER_128;
  hspi2.Init.FirstBit = SPI_FIRSTBIT_MSB;
  hspi2.Init.TIMode = SPI_TIMODE_DISABLE;
  hspi2.Init.CRCCalculation = SPI_CRCCALCULATION_DISABLE;
  hspi2.Init.CRCPolynomial = 10;
  if (HAL_SPI_Init(&hspi2) != HAL_OK)
  {
    Error_Handler();
  }

}

static void MX_TIM3_Init(void)
{

  TIM_ClockConfigTypeDef sClockSourceConfig = {0};
  TIM_MasterConfigTypeDef sMasterConfig = {0};
  TIM_OC_InitTypeDef sConfigOC = {0};

  htim3.Instance = TIM3;
  htim3.Init.Prescaler = 0;
  htim3.Init.CounterMode = TIM_COUNTERMODE_UP;
  htim3.Init.Period = 65535;
  htim3.Init.ClockDivision = TIM_CLOCKDIVISION_DIV1;
  htim3.Init.AutoReloadPreload = TIM_AUTORELOAD_PRELOAD_DISABLE;
  if (HAL_TIM_Base_Init(&htim3) != HAL_OK)
  {
    Error_Handler();
  }
  sClockSourceConfig.ClockSource = TIM_CLOCKSOURCE_INTERNAL;
  if (HAL_TIM_ConfigClockSource(&htim3, &sClockSourceConfig) != HAL_OK)
  {
    Error_Handler();
  }
  if (HAL_TIM_PWM_Init(&htim3) != HAL_OK)
  {
    Error_Handler();
  }
  sMasterConfig.MasterOutputTrigger = TIM_TRGO_RESET;
  sMasterConfig.MasterSlaveMode = TIM_MASTERSLAVEMODE_DISABLE;
  if (HAL_TIMEx_MasterConfigSynchronization(&htim3, &sMasterConfig) != HAL_OK)
  {
    Error_Handler();
  }
  sConfigOC.OCMode = TIM_OCMODE_PWM1;
  sConfigOC.Pulse = 0;
  sConfigOC.OCPolarity = TIM_OCPOLARITY_HIGH;
  sConfigOC.OCFastMode = TIM_OCFAST_DISABLE;
  if (HAL_TIM_PWM_ConfigChannel(&htim3, &sConfigOC, TIM_CHANNEL_4) != HAL_OK)
  {
    Error_Handler();
  }
  HAL_TIM_MspPostInit(&htim3);

}

static void MX_TIM4_Init(void)
{

  TIM_ClockConfigTypeDef sClockSourceConfig = {0};
  TIM_MasterConfigTypeDef sMasterConfig = {0};

  htim4.Instance = TIM4;
  htim4.Init.Prescaler = 800;
  htim4.Init.CounterMode = TIM_COUNTERMODE_UP;
  htim4.Init.Period = 1;
  htim4.Init.ClockDivision = TIM_CLOCKDIVISION_DIV1;
  htim4.Init.AutoReloadPreload = TIM_AUTORELOAD_PRELOAD_DISABLE;
  if (HAL_TIM_Base_Init(&htim4) != HAL_OK)
  {
    Error_Handler();
  }
  sClockSourceConfig.ClockSource = TIM_CLOCKSOURCE_INTERNAL;
  if (HAL_TIM_ConfigClockSource(&htim4, &sClockSourceConfig) != HAL_OK)
  {
    Error_Handler();
  }
  sMasterConfig.MasterOutputTrigger = TIM_TRGO_UPDATE;
  sMasterConfig.MasterSlaveMode = TIM_MASTERSLAVEMODE_DISABLE;
  if (HAL_TIMEx_MasterConfigSynchronization(&htim4, &sMasterConfig) != HAL_OK)
  {
    Error_Handler();
  }

}

static void MX_TIM5_Init(void)
{

  TIM_ClockConfigTypeDef sClockSourceConfig = {0};
  TIM_MasterConfigTypeDef sMasterConfig = {0};

  htim5.Instance = TIM5;
  htim5.Init.Prescaler = 873;
  htim5.Init.CounterMode = TIM_COUNTERMODE_UP;
  htim5.Init.Period = 1;
  htim5.Init.ClockDivision = TIM_CLOCKDIVISION_DIV1;
  htim5.Init.AutoReloadPreload = TIM_AUTORELOAD_PRELOAD_DISABLE;
  if (HAL_TIM_Base_Init(&htim5) != HAL_OK)
  {
    Error_Handler();
  }
  sClockSourceConfig.ClockSource = TIM_CLOCKSOURCE_INTERNAL;
  if (HAL_TIM_ConfigClockSource(&htim5, &sClockSourceConfig) != HAL_OK)
  {
    Error_Handler();
  }
  sMasterConfig.MasterOutputTrigger = TIM_TRGO_UPDATE;
  sMasterConfig.MasterSlaveMode = TIM_MASTERSLAVEMODE_DISABLE;
  if (HAL_TIMEx_MasterConfigSynchronization(&htim5, &sMasterConfig) != HAL_OK)
  {
    Error_Handler();
  }

}

static void MX_TIM6_Init(void)
{

  TIM_MasterConfigTypeDef sMasterConfig = {0};

  htim6.Instance = TIM6;
  htim6.Init.Prescaler = 41999;
  htim6.Init.CounterMode = TIM_COUNTERMODE_UP;
  htim6.Init.Period = 99;
  htim6.Init.AutoReloadPreload = TIM_AUTORELOAD_PRELOAD_DISABLE;
  if (HAL_TIM_Base_Init(&htim6) != HAL_OK)
  {
    Error_Handler();
  }
  sMasterConfig.MasterOutputTrigger = TIM_TRGO_UPDATE;
  sMasterConfig.MasterSlaveMode = TIM_MASTERSLAVEMODE_DISABLE;
  if (HAL_TIMEx_MasterConfigSynchronization(&htim6, &sMasterConfig) != HAL_OK)
  {
    Error_Handler();
  }

}

static void MX_TIM7_Init(void)
{

  TIM_MasterConfigTypeDef sMasterConfig = {0};

  htim7.Instance = TIM7;
  htim7.Init.Prescaler = 800;
  htim7.Init.CounterMode = TIM_COUNTERMODE_UP;
  htim7.Init.Period = 1;
  htim7.Init.AutoReloadPreload = TIM_AUTORELOAD_PRELOAD_DISABLE;
  if (HAL_TIM_Base_Init(&htim7) != HAL_OK)
  {
    Error_Handler();
  }
  sMasterConfig.MasterOutputTrigger = TIM_TRGO_UPDATE;
  sMasterConfig.MasterSlaveMode = TIM_MASTERSLAVEMODE_DISABLE;
  if (HAL_TIMEx_MasterConfigSynchronization(&htim7, &sMasterConfig) != HAL_OK)
  {
    Error_Handler();
  }

}

static void MX_USART1_UART_Init(void)
{

  huart1.Instance = USART1;
  huart1.Init.BaudRate = 115200;
  huart1.Init.WordLength = UART_WORDLENGTH_8B;
  huart1.Init.StopBits = UART_STOPBITS_1;
  huart1.Init.Parity = UART_PARITY_NONE;
  huart1.Init.Mode = UART_MODE_TX_RX;
  huart1.Init.HwFlowCtl = UART_HWCONTROL_NONE;
  huart1.Init.OverSampling = UART_OVERSAMPLING_16;
  if (HAL_UART_Init(&huart1) != HAL_OK)
  {
    Error_Handler();
  }

}

static void MX_USART6_UART_Init(void)
{

  huart6.Instance = USART6;
  huart6.Init.BaudRate = 115200;
  huart6.Init.WordLength = UART_WORDLENGTH_8B;
  huart6.Init.StopBits = UART_STOPBITS_1;
  huart6.Init.Parity = UART_PARITY_NONE;
  huart6.Init.Mode = UART_MODE_TX_RX;
  huart6.Init.HwFlowCtl = UART_HWCONTROL_NONE;
  huart6.Init.OverSampling = UART_OVERSAMPLING_16;
  if (HAL_UART_Init(&huart6) != HAL_OK)
  {
    Error_Handler();
  }

}

static void MX_USB_OTG_FS_PCD_Init(void)
{

  hpcd_USB_OTG_FS.Instance = USB_OTG_FS;
  hpcd_USB_OTG_FS.Init.dev_endpoints = 4;
  hpcd_USB_OTG_FS.Init.speed = PCD_SPEED_FULL;
  hpcd_USB_OTG_FS.Init.dma_enable = DISABLE;
  hpcd_USB_OTG_FS.Init.phy_itface = PCD_PHY_EMBEDDED;
  hpcd_USB_OTG_FS.Init.Sof_enable = ENABLE;
  hpcd_USB_OTG_FS.Init.low_power_enable = DISABLE;
  hpcd_USB_OTG_FS.Init.lpm_enable = DISABLE;
  hpcd_USB_OTG_FS.Init.vbus_sensing_enable = DISABLE;
  hpcd_USB_OTG_FS.Init.use_dedicated_ep1 = DISABLE;
  if (HAL_PCD_Init(&hpcd_USB_OTG_FS) != HAL_OK)
  {
    Error_Handler();
  }

}

static void MX_DMA_Init(void)
{

  /* DMA controller clock enable */
  __HAL_RCC_DMA1_CLK_ENABLE();
  __HAL_RCC_DMA2_CLK_ENABLE();

  /* Configure DMA request hdma_memtomem_dma2_stream0 on DMA2_Stream0 */
  hdma_memtomem_dma2_stream0.Instance = DMA2_Stream0;
  hdma_memtomem_dma2_stream0.Init.Channel = DMA_CHANNEL_0;
  hdma_memtomem_dma2_stream0.Init.Direction = DMA_MEMORY_TO_MEMORY;
  hdma_memtomem_dma2_stream0.Init.PeriphInc = DMA_PINC_ENABLE;
  hdma_memtomem_dma2_stream0.Init.MemInc = DMA_MINC_ENABLE;
  hdma_memtomem_dma2_stream0.Init.PeriphDataAlignment = DMA_PDATAALIGN_WORD;
  hdma_memtomem_dma2_stream0.Init.MemDataAlignment = DMA_MDATAALIGN_WORD;
  hdma_memtomem_dma2_stream0.Init.Mode = DMA_NORMAL;
  hdma_memtomem_dma2_stream0.Init.Priority = DMA_PRIORITY_HIGH;
  hdma_memtomem_dma2_stream0.Init.FIFOMode = DMA_FIFOMODE_ENABLE;
  hdma_memtomem_dma2_stream0.Init.FIFOThreshold = DMA_FIFO_THRESHOLD_FULL;
  hdma_memtomem_dma2_stream0.Init.MemBurst = DMA_MBURST_INC4;
  hdma_memtomem_dma2_stream0.Init.PeriphBurst = DMA_PBURST_INC4;
  if (HAL_DMA_Init(&hdma_memtomem_dma2_stream0) != HAL_OK)
  {
    Error_Handler( );
  }

  /* Configure DMA request hdma_memtomem_dma2_stream1 on DMA2_Stream1 */
  hdma_memtomem_dma2_stream1.Instance = DMA2_Stream1;
  hdma_memtomem_dma2_stream1.Init.Channel = DMA_CHANNEL_0;
  hdma_memtomem_dma2_stream1.Init.Direction = DMA_MEMORY_TO_MEMORY;
  hdma_memtomem_dma2_stream1.Init.PeriphInc = DMA_PINC_ENABLE;
  hdma_memtomem_dma2_stream1.Init.MemInc = DMA_MINC_ENABLE;
  hdma_memtomem_dma2_stream1.Init.PeriphDataAlignment = DMA_PDATAALIGN_WORD;
  hdma_memtomem_dma2_stream1.Init.MemDataAlignment = DMA_MDATAALIGN_WORD;
  hdma_memtomem_dma2_stream1.Init.Mode = DMA_NORMAL;
  hdma_memtomem_dma2_stream1.Init.Priority = DMA_PRIORITY_HIGH;
  hdma_memtomem_dma2_stream1.Init.FIFOMode = DMA_FIFOMODE_ENABLE;
  hdma_memtomem_dma2_stream1.Init.FIFOThreshold = DMA_FIFO_THRESHOLD_FULL;
  hdma_memtomem_dma2_stream1.Init.MemBurst = DMA_MBURST_INC4;
  hdma_memtomem_dma2_stream1.Init.PeriphBurst = DMA_PBURST_INC4;
  if (HAL_DMA_Init(&hdma_memtomem_dma2_stream1) != HAL_OK)
  {
    Error_Handler( );
  }

  /* Configure DMA request hdma_memtomem_dma2_stream7 on DMA2_Stream7 */
  hdma_memtomem_dma2_stream7.Instance = DMA2_Stream7;
  hdma_memtomem_dma2_stream7.Init.Channel = DMA_CHANNEL_0;
  hdma_memtomem_dma2_stream7.Init.Direction = DMA_MEMORY_TO_MEMORY;
  hdma_memtomem_dma2_stream7.Init.PeriphInc = DMA_PINC_ENABLE;
  hdma_memtomem_dma2_stream7.Init.MemInc = DMA_MINC_ENABLE;
  hdma_memtomem_dma2_stream7.Init.PeriphDataAlignment = DMA_PDATAALIGN_WORD;
  hdma_memtomem_dma2_stream7.Init.MemDataAlignment = DMA_MDATAALIGN_WORD;
  hdma_memtomem_dma2_stream7.Init.Mode = DMA_NORMAL;
  hdma_memtomem_dma2_stream7.Init.Priority = DMA_PRIORITY_LOW;
  hdma_memtomem_dma2_stream7.Init.FIFOMode = DMA_FIFOMODE_ENABLE;
  hdma_memtomem_dma2_stream7.Init.FIFOThreshold = DMA_FIFO_THRESHOLD_FULL;
  hdma_memtomem_dma2_stream7.Init.MemBurst = DMA_MBURST_INC4;
  hdma_memtomem_dma2_stream7.Init.PeriphBurst = DMA_PBURST_INC4;
  if (HAL_DMA_Init(&hdma_memtomem_dma2_stream7) != HAL_OK)
  {
    Error_Handler( );
  }

  /* Configure DMA request hdma_memtomem_dma2_stream6 on DMA2_Stream6 */
  hdma_memtomem_dma2_stream6.Instance = DMA2_Stream6;
  hdma_memtomem_dma2_stream6.Init.Channel = DMA_CHANNEL_0;
  hdma_memtomem_dma2_stream6.Init.Direction = DMA_MEMORY_TO_MEMORY;
  hdma_memtomem_dma2_stream6.Init.PeriphInc = DMA_PINC_ENABLE;
  hdma_memtomem_dma2_stream6.Init.MemInc = DMA_MINC_DISABLE;
  hdma_memtomem_dma2_stream6.Init.PeriphDataAlignment = DMA_PDATAALIGN_HALFWORD;
  hdma_memtomem_dma2_stream6.Init.MemDataAlignment = DMA_MDATAALIGN_HALFWORD;
  hdma_memtomem_dma2_stream6.Init.Mode = DMA_NORMAL;
  hdma_memtomem_dma2_stream6.Init.Priority = DMA_PRIORITY_LOW;
  hdma_memtomem_dma2_stream6.Init.FIFOMode = DMA_FIFOMODE_ENABLE;
  hdma_memtomem_dma2_stream6.Init.FIFOThreshold = DMA_FIFO_THRESHOLD_FULL;
  hdma_memtomem_dma2_stream6.Init.MemBurst = DMA_MBURST_INC8;
  hdma_memtomem_dma2_stream6.Init.PeriphBurst = DMA_PBURST_INC8;
  if (HAL_DMA_Init(&hdma_memtomem_dma2_stream6) != HAL_OK)
  {
    Error_Handler( );
  }

  /* Configure DMA request hdma_memtomem_dma2_stream5 on DMA2_Stream5 */
  hdma_memtomem_dma2_stream5.Instance = DMA2_Stream5;
  hdma_memtomem_dma2_stream5.Init.Channel = DMA_CHANNEL_0;
  hdma_memtomem_dma2_stream5.Init.Direction = DMA_MEMORY_TO_MEMORY;
  hdma_memtomem_dma2_stream5.Init.PeriphInc = DMA_PINC_DISABLE;
  hdma_memtomem_dma2_stream5.Init.MemInc = DMA_MINC_DISABLE;
  hdma_memtomem_dma2_stream5.Init.PeriphDataAlignment = DMA_PDATAALIGN_HALFWORD;
  hdma_memtomem_dma2_stream5.Init.MemDataAlignment = DMA_MDATAALIGN_HALFWORD;
  hdma_memtomem_dma2_stream5.Init.Mode = DMA_NORMAL;
  hdma_memtomem_dma2_stream5.Init.Priority = DMA_PRIORITY_MEDIUM;
  hdma_memtomem_dma2_stream5.Init.FIFOMode = DMA_FIFOMODE_ENABLE;
  hdma_memtomem_dma2_stream5.Init.FIFOThreshold = DMA_FIFO_THRESHOLD_FULL;
  hdma_memtomem_dma2_stream5.Init.MemBurst = DMA_MBURST_INC8;
  hdma_memtomem_dma2_stream5.Init.PeriphBurst = DMA_PBURST_INC8;
  if (HAL_DMA_Init(&hdma_memtomem_dma2_stream5) != HAL_OK)
  {
    Error_Handler( );
  }

  /* Configure DMA request hdma_memtomem_dma2_stream3 on DMA2_Stream3 */
  hdma_memtomem_dma2_stream3.Instance = DMA2_Stream3;
  hdma_memtomem_dma2_stream3.Init.Channel = DMA_CHANNEL_0;
  hdma_memtomem_dma2_stream3.Init.Direction = DMA_MEMORY_TO_MEMORY;
  hdma_memtomem_dma2_stream3.Init.PeriphInc = DMA_PINC_ENABLE;
  hdma_memtomem_dma2_stream3.Init.MemInc = DMA_MINC_ENABLE;
  hdma_memtomem_dma2_stream3.Init.PeriphDataAlignment = DMA_PDATAALIGN_WORD;
  hdma_memtomem_dma2_stream3.Init.MemDataAlignment = DMA_MDATAALIGN_WORD;
  hdma_memtomem_dma2_stream3.Init.Mode = DMA_NORMAL;
  hdma_memtomem_dma2_stream3.Init.Priority = DMA_PRIORITY_HIGH;
  hdma_memtomem_dma2_stream3.Init.FIFOMode = DMA_FIFOMODE_ENABLE;
  hdma_memtomem_dma2_stream3.Init.FIFOThreshold = DMA_FIFO_THRESHOLD_FULL;
  hdma_memtomem_dma2_stream3.Init.MemBurst = DMA_MBURST_INC4;
  hdma_memtomem_dma2_stream3.Init.PeriphBurst = DMA_PBURST_INC4;
  if (HAL_DMA_Init(&hdma_memtomem_dma2_stream3) != HAL_OK)
  {
    Error_Handler( );
  }

  /* DMA interrupt init */
  /* DMA1_Stream0_IRQn interrupt configuration */
  HAL_NVIC_SetPriority(DMA1_Stream0_IRQn, 0, 0);
  HAL_NVIC_EnableIRQ(DMA1_Stream0_IRQn);
  /* DMA1_Stream5_IRQn interrupt configuration */
  HAL_NVIC_SetPriority(DMA1_Stream5_IRQn, 0, 0);
  HAL_NVIC_EnableIRQ(DMA1_Stream5_IRQn);
  /* DMA2_Stream0_IRQn interrupt configuration */
  HAL_NVIC_SetPriority(DMA2_Stream0_IRQn, 4, 0);
  HAL_NVIC_EnableIRQ(DMA2_Stream0_IRQn);
  /* DMA2_Stream1_IRQn interrupt configuration */
  HAL_NVIC_SetPriority(DMA2_Stream1_IRQn, 4, 0);
  HAL_NVIC_EnableIRQ(DMA2_Stream1_IRQn);
  /* DMA2_Stream2_IRQn interrupt configuration */
  HAL_NVIC_SetPriority(DMA2_Stream2_IRQn, 0, 0);
  HAL_NVIC_EnableIRQ(DMA2_Stream2_IRQn);
  /* DMA2_Stream3_IRQn interrupt configuration */
  HAL_NVIC_SetPriority(DMA2_Stream3_IRQn, 0, 0);
  HAL_NVIC_EnableIRQ(DMA2_Stream3_IRQn);
  /* DMA2_Stream6_IRQn interrupt configuration */
  HAL_NVIC_SetPriority(DMA2_Stream6_IRQn, 5, 0);
  HAL_NVIC_EnableIRQ(DMA2_Stream6_IRQn);

}

static void MX_GPIO_Init(void)
{
  GPIO_InitTypeDef GPIO_InitStruct = {0};

  /* GPIO Ports Clock Enable */
  __HAL_RCC_GPIOE_CLK_ENABLE();
  __HAL_RCC_GPIOC_CLK_ENABLE();
  __HAL_RCC_GPIOH_CLK_ENABLE();
  __HAL_RCC_GPIOA_CLK_ENABLE();
  __HAL_RCC_GPIOB_CLK_ENABLE();
  __HAL_RCC_GPIOD_CLK_ENABLE();

  /*Configure GPIO pin Output Level */
  HAL_GPIO_WritePin(GPIOA, BUS_COMM_SDA_Pin|BUS_COMM_SCK_Pin|AD2_CS_Pin, GPIO_PIN_RESET);

  /*Configure GPIO pin Output Level */
  HAL_GPIO_WritePin(GPIOB, W26Q16_CS_Pin|W25Q16_SCK_Pin|W25Q16_MISO_Pin|W25Q16_MOSI_Pin
                          |RFUNIT_RCLK_Pin|RFUNIT_CLK_Pin|RFUNIT_DATA_Pin, GPIO_PIN_RESET);

  /*Configure GPIO pin Output Level */
  HAL_GPIO_WritePin(GPIOD, SD_CS_Pin|F_CS_Pin|WM8731_SCK_Pin|WM8731_SDA_Pin, GPIO_PIN_RESET);

  /*Configure GPIO pin Output Level */
  HAL_GPIO_WritePin(AD1_CS_GPIO_Port, AD1_CS_Pin, GPIO_PIN_RESET);

  /*Configure GPIO pin : ENC_DT_Pin */
  GPIO_InitStruct.Pin = ENC_DT_Pin;
  GPIO_InitStruct.Mode = GPIO_MODE_IT_RISING_FALLING;
  GPIO_InitStruct.Pull = GPIO_PULLUP;
  HAL_GPIO_Init(ENC_DT_GPIO_Port, &GPIO_InitStruct);

  /*Configure GPIO pin : PE3 */
  GPIO_InitStruct.Pin = GPIO_PIN_3;
  GPIO_InitStruct.Mode = GPIO_MODE_ANALOG;
  GPIO_InitStruct.Pull = GPIO_NOPULL;
  HAL_GPIO_Init(GPIOE, &GPIO_InitStruct);

  /*Configure GPIO pins : ENC2_SW_Pin ENC2_DT_Pin */
  GPIO_InitStruct.Pin = ENC2_SW_Pin|ENC2_DT_Pin;
  GPIO_InitStruct.Mode = GPIO_MODE_INPUT;
  GPIO_InitStruct.Pull = GPIO_NOPULL;
  HAL_GPIO_Init(GPIOE, &GPIO_InitStruct);

  /*Configure GPIO pins : ENC_CLK_Pin KEY_IN_DASH_Pin KEY_IN_DOT_Pin */
  GPIO_InitStruct.Pin = ENC_CLK_Pin|KEY_IN_DASH_Pin|KEY_IN_DOT_Pin;
  GPIO_InitStruct.Mode = GPIO_MODE_INPUT;
  GPIO_InitStruct.Pull = GPIO_PULLUP;
  HAL_GPIO_Init(GPIOE, &GPIO_InitStruct);

  /*Configure GPIO pin : ENC2_CLK_Pin */
  GPIO_InitStruct.Pin = ENC2_CLK_Pin;
  GPIO_InitStruct.Mode = GPIO_MODE_INPUT;
  GPIO_InitStruct.Pull = GPIO_NOPULL;
  HAL_GPIO_Init(ENC2_CLK_GPIO_Port, &GPIO_InitStruct);

  /*Configure GPIO pins : PC0 PC1 */
  GPIO_InitStruct.Pin = GPIO_PIN_0|GPIO_PIN_1;
  GPIO_InitStruct.Mode = GPIO_MODE_ANALOG;
  GPIO_InitStruct.Pull = GPIO_NOPULL;
  HAL_GPIO_Init(GPIOC, &GPIO_InitStruct);

  /*Configure GPIO pins : PA0 PA1 */
  GPIO_InitStruct.Pin = GPIO_PIN_0|GPIO_PIN_1;
  GPIO_InitStruct.Mode = GPIO_MODE_ANALOG;
  GPIO_InitStruct.Pull = GPIO_NOPULL;
  HAL_GPIO_Init(GPIOA, &GPIO_InitStruct);

  /*Configure GPIO pins : BUS_COMM_SDA_Pin BUS_COMM_SCK_Pin */
  GPIO_InitStruct.Pin = BUS_COMM_SDA_Pin|BUS_COMM_SCK_Pin;
  GPIO_InitStruct.Mode = GPIO_MODE_OUTPUT_PP;
  GPIO_InitStruct.Pull = GPIO_PULLUP;
  GPIO_InitStruct.Speed = GPIO_SPEED_FREQ_LOW;
  HAL_GPIO_Init(GPIOA, &GPIO_InitStruct);

  /*Configure GPIO pin : PTT_IN_Pin */
  GPIO_InitStruct.Pin = PTT_IN_Pin;
  GPIO_InitStruct.Mode = GPIO_MODE_IT_RISING;
  GPIO_InitStruct.Pull = GPIO_PULLUP;
  HAL_GPIO_Init(PTT_IN_GPIO_Port, &GPIO_InitStruct);

  /*Configure GPIO pin : LED_PEN_Pin */
  GPIO_InitStruct.Pin = LED_PEN_Pin;
  GPIO_InitStruct.Mode = GPIO_MODE_IT_RISING_FALLING;
  GPIO_InitStruct.Pull = GPIO_PULLUP;
  HAL_GPIO_Init(LED_PEN_GPIO_Port, &GPIO_InitStruct);

  /*Configure GPIO pin : W26Q16_CS_Pin */
  GPIO_InitStruct.Pin = W26Q16_CS_Pin;
  GPIO_InitStruct.Mode = GPIO_MODE_OUTPUT_PP;
  GPIO_InitStruct.Pull = GPIO_PULLUP;
  GPIO_InitStruct.Speed = GPIO_SPEED_FREQ_VERY_HIGH;
  HAL_GPIO_Init(W26Q16_CS_GPIO_Port, &GPIO_InitStruct);

  /*Configure GPIO pins : PB2 PB11 PB9 */
  GPIO_InitStruct.Pin = GPIO_PIN_2|GPIO_PIN_11|GPIO_PIN_9;
  GPIO_InitStruct.Mode = GPIO_MODE_ANALOG;
  GPIO_InitStruct.Pull = GPIO_NOPULL;
  HAL_GPIO_Init(GPIOB, &GPIO_InitStruct);

  /*Configure GPIO pin : AUDIO_48K_CLOCK_Pin */
  GPIO_InitStruct.Pin = AUDIO_48K_CLOCK_Pin;
  GPIO_InitStruct.Mode = GPIO_MODE_IT_RISING;
  GPIO_InitStruct.Pull = GPIO_PULLUP;
  HAL_GPIO_Init(AUDIO_48K_CLOCK_GPIO_Port, &GPIO_InitStruct);

  /*Configure GPIO pins : SD_CS_Pin F_CS_Pin */
  GPIO_InitStruct.Pin = SD_CS_Pin|F_CS_Pin;
  GPIO_InitStruct.Mode = GPIO_MODE_OUTPUT_PP;
  GPIO_InitStruct.Pull = GPIO_NOPULL;
  GPIO_InitStruct.Speed = GPIO_SPEED_FREQ_LOW;
  HAL_GPIO_Init(GPIOD, &GPIO_InitStruct);

  /*Configure GPIO pin : AD1_CS_Pin */
  GPIO_InitStruct.Pin = AD1_CS_Pin;
  GPIO_InitStruct.Mode = GPIO_MODE_OUTPUT_PP;
  GPIO_InitStruct.Pull = GPIO_NOPULL;
  GPIO_InitStruct.Speed = GPIO_SPEED_FREQ_LOW;
  HAL_GPIO_Init(AD1_CS_GPIO_Port, &GPIO_InitStruct);

  /*Configure GPIO pin : AUDIO_I2S_CLOCK_Pin */
  GPIO_InitStruct.Pin = AUDIO_I2S_CLOCK_Pin;
  GPIO_InitStruct.Mode = GPIO_MODE_AF_PP;
  GPIO_InitStruct.Pull = GPIO_PULLUP;
  GPIO_InitStruct.Speed = GPIO_SPEED_FREQ_VERY_HIGH;
  GPIO_InitStruct.Alternate = GPIO_AF5_SPI1;
  HAL_GPIO_Init(AUDIO_I2S_CLOCK_GPIO_Port, &GPIO_InitStruct);

  /*Configure GPIO pin : AD2_CS_Pin */
  GPIO_InitStruct.Pin = AD2_CS_Pin;
  GPIO_InitStruct.Mode = GPIO_MODE_OUTPUT_PP;
  GPIO_InitStruct.Pull = GPIO_NOPULL;
  GPIO_InitStruct.Speed = GPIO_SPEED_FREQ_LOW;
  HAL_GPIO_Init(AD2_CS_GPIO_Port, &GPIO_InitStruct);

  /*Configure GPIO pin : PD2 */
  GPIO_InitStruct.Pin = GPIO_PIN_2;
  GPIO_InitStruct.Mode = GPIO_MODE_ANALOG;
  GPIO_InitStruct.Pull = GPIO_NOPULL;
  HAL_GPIO_Init(GPIOD, &GPIO_InitStruct);

  /*Configure GPIO pins : WM8731_SCK_Pin WM8731_SDA_Pin */
  GPIO_InitStruct.Pin = WM8731_SCK_Pin|WM8731_SDA_Pin;
  GPIO_InitStruct.Mode = GPIO_MODE_OUTPUT_PP;
  GPIO_InitStruct.Pull = GPIO_PULLUP;
  GPIO_InitStruct.Speed = GPIO_SPEED_FREQ_LOW;
  HAL_GPIO_Init(GPIOD, &GPIO_InitStruct);

  /*Configure GPIO pins : W25Q16_SCK_Pin W25Q16_MISO_Pin W25Q16_MOSI_Pin */
  GPIO_InitStruct.Pin = W25Q16_SCK_Pin|W25Q16_MISO_Pin|W25Q16_MOSI_Pin;
  GPIO_InitStruct.Mode = GPIO_MODE_OUTPUT_PP;
  GPIO_InitStruct.Pull = GPIO_NOPULL;
  GPIO_InitStruct.Speed = GPIO_SPEED_FREQ_LOW;
  HAL_GPIO_Init(GPIOB, &GPIO_InitStruct);

  /*Configure GPIO pins : RFUNIT_RCLK_Pin RFUNIT_CLK_Pin RFUNIT_DATA_Pin */
  GPIO_InitStruct.Pin = RFUNIT_RCLK_Pin|RFUNIT_CLK_Pin|RFUNIT_DATA_Pin;
  GPIO_InitStruct.Mode = GPIO_MODE_OUTPUT_PP;
  GPIO_InitStruct.Pull = GPIO_PULLUP;
  GPIO_InitStruct.Speed = GPIO_SPEED_FREQ_LOW;
  HAL_GPIO_Init(GPIOB, &GPIO_InitStruct);

  /* EXTI interrupt init*/
  HAL_NVIC_SetPriority(EXTI2_IRQn, 3, 0);
  HAL_NVIC_EnableIRQ(EXTI2_IRQn);

  HAL_NVIC_SetPriority(EXTI4_IRQn, 6, 0);
  HAL_NVIC_EnableIRQ(EXTI4_IRQn);

  HAL_NVIC_SetPriority(EXTI9_5_IRQn, 5, 0);
  HAL_NVIC_EnableIRQ(EXTI9_5_IRQn);

  HAL_NVIC_SetPriority(EXTI15_10_IRQn, 2, 0);
  HAL_NVIC_EnableIRQ(EXTI15_10_IRQn);

}

/* FSMC initialization function */
static void MX_FSMC_Init(void)
{

  FSMC_NORSRAM_TimingTypeDef Timing = {0};
  FSMC_NORSRAM_TimingTypeDef ExtTiming = {0};

  /** Perform the SRAM1 memory initialization sequence
  */
  hsram1.Instance = FSMC_NORSRAM_DEVICE;
  hsram1.Extended = FSMC_NORSRAM_EXTENDED_DEVICE;
  /* hsram1.Init */
  hsram1.Init.NSBank = FSMC_NORSRAM_BANK1;
  hsram1.Init.DataAddressMux = FSMC_DATA_ADDRESS_MUX_DISABLE;
  hsram1.Init.MemoryType = FSMC_MEMORY_TYPE_SRAM;
  hsram1.Init.MemoryDataWidth = FSMC_NORSRAM_MEM_BUS_WIDTH_16;
  hsram1.Init.BurstAccessMode = FSMC_BURST_ACCESS_MODE_DISABLE;
  hsram1.Init.WaitSignalPolarity = FSMC_WAIT_SIGNAL_POLARITY_LOW;
  hsram1.Init.WrapMode = FSMC_WRAP_MODE_DISABLE;
  hsram1.Init.WaitSignalActive = FSMC_WAIT_TIMING_BEFORE_WS;
  hsram1.Init.WriteOperation = FSMC_WRITE_OPERATION_ENABLE;
  hsram1.Init.WaitSignal = FSMC_WAIT_SIGNAL_DISABLE;
  hsram1.Init.ExtendedMode = FSMC_EXTENDED_MODE_ENABLE;
  hsram1.Init.AsynchronousWait = FSMC_ASYNCHRONOUS_WAIT_DISABLE;
  hsram1.Init.WriteBurst = FSMC_WRITE_BURST_DISABLE;
  hsram1.Init.PageSize = FSMC_PAGE_SIZE_NONE;
  /* Timing */
  Timing.AddressSetupTime = 2;
  Timing.AddressHoldTime = 15;
  Timing.DataSetupTime = 5;
  Timing.BusTurnAroundDuration = 5;
  Timing.CLKDivision = 16;
  Timing.DataLatency = 17;
  Timing.AccessMode = FSMC_ACCESS_MODE_A;
  /* ExtTiming */
  ExtTiming.AddressSetupTime = 2;
  ExtTiming.AddressHoldTime = 15;
  ExtTiming.DataSetupTime = 5;
  ExtTiming.BusTurnAroundDuration = 3;
  ExtTiming.CLKDivision = 16;
  ExtTiming.DataLatency = 17;
  ExtTiming.AccessMode = FSMC_ACCESS_MODE_A;

  if (HAL_SRAM_Init(&hsram1, &Timing, &ExtTiming) != HAL_OK)
  {
    Error_Handler( );
  }

}

void Error_Handler(void)
{
	while (1)
	{
	}
}

/************************ (C) COPYRIGHT STMicroelectronics *****END OF FILE****/
